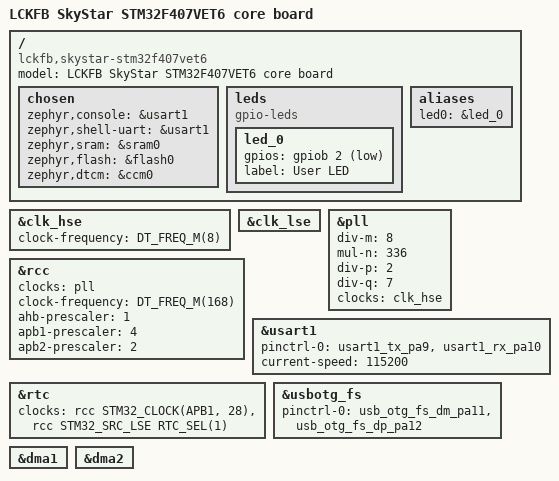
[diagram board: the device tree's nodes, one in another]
/*
* Copyright (c) 2025 O431
*
* SPDX-License-Identifier: MIT
*
* Zephyr board description for the LCKFB SkyStar STM32F407VET6 core board.
*/

/dts-v1/;

#include <st/f4/stm32f407Xe.dtsi>
#include <st/f4/stm32f407v(e-g)tx-pinctrl.dtsi>

/ {
	model = "LCKFB SkyStar STM32F407VET6 core board";
	compatible = "lckfb,skystar-stm32f407vet6";

	chosen {
		zephyr,console = &usart1;
		zephyr,shell-uart = &usart1;
		zephyr,sram = &sram0;
		zephyr,flash = &flash0;
		zephyr,dtcm = &ccm0;
	};

	leds: leds {
		compatible = "gpio-leds";

		led_0: led_0 {
			gpios = <&gpiob 2 GPIO_ACTIVE_LOW>;
			label = "User LED";
		};
	};

	aliases {
		led0 = &led_0;
	};
};

&clk_hse {
	clock-frequency = <DT_FREQ_M(8)>;
	status = "okay";
};

&clk_lse {
	status = "okay";
};

&pll {
	div-m = <8>;
	mul-n = <336>;
	div-p = <2>;
	div-q = <7>;
	clocks = <&clk_hse>;
	status = "okay";
};

&rcc {
	clocks = <&pll>;
	clock-frequency = <DT_FREQ_M(168)>;
	ahb-prescaler = <1>;
	apb1-prescaler = <4>;
	apb2-prescaler = <2>;
};

&usart1 {
	pinctrl-0 = <&usart1_tx_pa9 &usart1_rx_pa10>;
	pinctrl-names = "default";
	current-speed = <115200>;
	status = "okay";
};

&rtc {
	clocks = <&rcc STM32_CLOCK(APB1, 28)>,
	<&rcc STM32_SRC_LSE RTC_SEL(1)>;
	status = "okay";
};

zephyr_udc0: &usbotg_fs {
	pinctrl-0 = <&usb_otg_fs_dm_pa11 &usb_otg_fs_dp_pa12>;
	pinctrl-names = "default";
	status = "okay";
};

&dma1 {
	status = "okay";
};

&dma2 {
	status = "okay";
};
